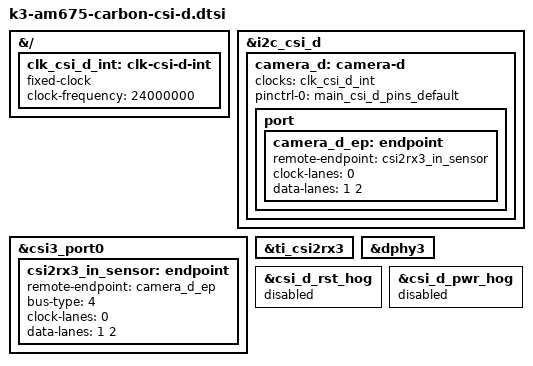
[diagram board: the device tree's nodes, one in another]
// SPDX-License-Identifier: GPL-2.0
/*
 * Digilent Pcam 5C 5MP OV5640 camera module
 *
 * Copyright (C) 2025 Ezurio LLC
 */

#include <dt-bindings/gpio/gpio.h>

&{/} {
	/* On Camera module oscillator */
	clk_csi_d_int: clk-csi-d-int {
		compatible = "fixed-clock";
		#clock-cells = <0>;
		clock-frequency = <24000000>;
	};
};

&i2c_csi_d {
	#address-cells = <1>;
	#size-cells = <0>;

	camera_d: camera-d {
		clocks = <&clk_csi_d_int>; /* On Camera module */
		clock-names = "xclk";

		pinctrl-names = "default";
		pinctrl-0 = <&main_csi_d_pins_default>;

		port {
			camera_d_ep: endpoint {
				remote-endpoint = <&csi2rx3_in_sensor>;
				clock-lanes = <0>;
				data-lanes = <1 2>;
			};
		};
	};
};

&csi3_port0 {
	status = "okay";

	csi2rx3_in_sensor: endpoint {
		remote-endpoint = <&camera_d_ep>;
		bus-type = <4>; /* CSI2 DPHY. */
		clock-lanes = <0>;
		data-lanes = <1 2>;
	};
};

&ti_csi2rx3 {
	status = "okay";
};

&dphy3 {
	status = "okay";
};

&csi_d_rst_hog {
	status = "disabled";
};

&csi_d_pwr_hog {
	status = "disabled";
};
